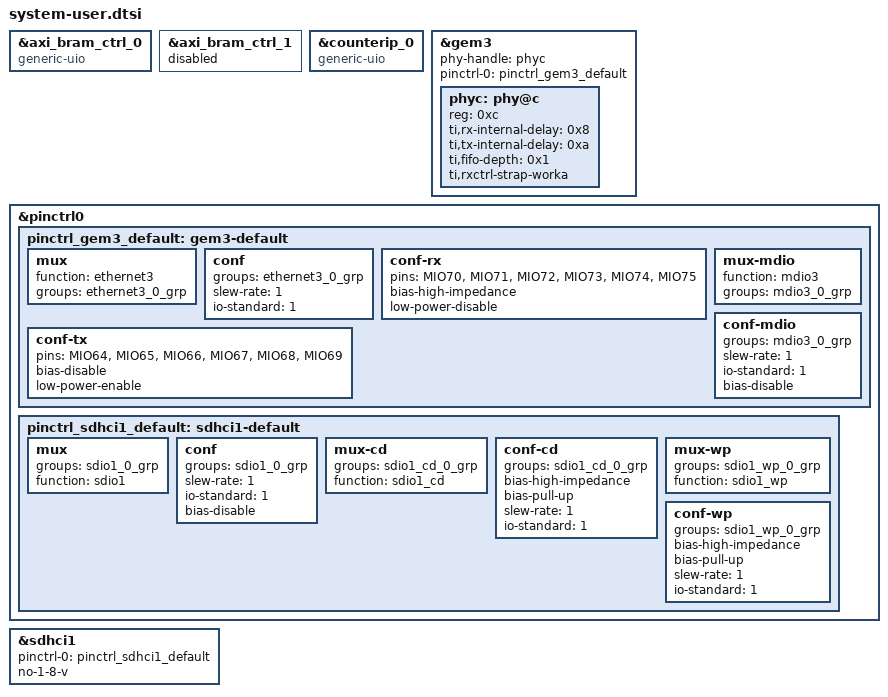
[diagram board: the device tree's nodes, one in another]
/include/ "system-conf.dtsi"
/ {
};

&axi_bram_ctrl_0 {
   compatible = "generic-uio";
};

&axi_bram_ctrl_1 {
   status = "disabled";
};

&counterip_0 {
   compatible = "generic-uio";
};

&gem3 {
	phy-handle = <&phyc>;
	pinctrl-names = "default";
	pinctrl-0 = <&pinctrl_gem3_default>;
	phyc: phy@c {
		reg = <0xc>;
		ti,rx-internal-delay = <0x8>;
		ti,tx-internal-delay = <0xa>;
		ti,fifo-depth = <0x1>;
		ti,rxctrl-strap-worka;
  };
};

&pinctrl0 {
	status = "okay";
	pinctrl_gem3_default: gem3-default {
		mux {
			function = "ethernet3";
			groups = "ethernet3_0_grp";
		};

		conf {
			groups = "ethernet3_0_grp";
			slew-rate = <1>;
			io-standard = <1>;
		};

		conf-rx {
			pins = "MIO70", "MIO71", "MIO72", "MIO73", "MIO74",
									"MIO75";
			bias-high-impedance;
			low-power-disable;
		};

		conf-tx {
			pins = "MIO64", "MIO65", "MIO66", "MIO67", "MIO68",
									"MIO69";
			bias-disable;
			low-power-enable;
		};

		mux-mdio {
			function = "mdio3";
			groups = "mdio3_0_grp";
		};

		conf-mdio {
			groups = "mdio3_0_grp";
			slew-rate = <1>;
			io-standard = <1>;
			bias-disable;
		};
	};

	pinctrl_sdhci1_default: sdhci1-default {
		mux {
			groups = "sdio1_0_grp";
			function = "sdio1";
		};

		conf {
			groups = "sdio1_0_grp";
			slew-rate = <1>;
			io-standard = <1>;
			bias-disable;
		};

		mux-cd {
			groups = "sdio1_cd_0_grp";
			function = "sdio1_cd";
		};

		conf-cd {
			groups = "sdio1_cd_0_grp";
			bias-high-impedance;
			bias-pull-up;
			slew-rate = <1>;
			io-standard = <1>;
		};

		mux-wp {
			groups = "sdio1_wp_0_grp";
			function = "sdio1_wp";
		};

		conf-wp {
			groups = "sdio1_wp_0_grp";
			bias-high-impedance;
			bias-pull-up;
			slew-rate = <1>;
			io-standard = <1>;
		};
	};   
  
}; 

/* SD1 with level shifter */
&sdhci1 {
	pinctrl-names = "default";
	pinctrl-0 = <&pinctrl_sdhci1_default>;
	no-1-8-v;
};  
